# STM32H743 register map
File version: 2.4
CPU: CM7 r0p1, little endian, MPU, FPU, 4 interrupt priority bits
Registers are 32-bit, read-write, reset 0x0 unless marked. A register's access mark holds for its fields unless they carry their own. Offsets are from the block's base; [hi:lo] are bit positions.

## VREFBUF
Base 0x58003C00
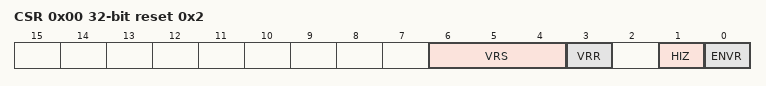
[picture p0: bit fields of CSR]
0x00 CSR access per field reset 0x2 — VREFBUF 控制与状态寄存器
  [6:4] VRS rw — 电压参考量程。这些位用于选择电压参考缓冲器产生的电压值。其他值：保留。
  [3] VRR ro — 电压参考缓冲器就绪
  [1] HIZ rw — 高阻抗模式。此位控制模拟开关与 VREF+ 引脚的连接或断开。有关基于 ENVR 位配置的模式说明，请参见表 196：VREF 缓冲器模式。
  [0] ENVR rw — 电压参考缓冲器模式使能。此位用于使能电压参考缓冲器模式。
0x04 CCR — VREFBUF 校准控制寄存器
  [5:0] TRIM — 微调代码。这些位在复位后会自动加载生产测试期间存入 Flash 的微调值。向这些位写入数据可微调内部参考缓冲器电压。

## IWDG — 独立看门狗
Base 0x58004800
0x00 KR wo — 键寄存器
  [15:0] KEY — 键值（只写，读取返回 0x0000）。软件必须定期向这些位写入键值 0xAAAA，否则当计数器递减到 0 时，看门狗将产生复位。写入键值 0x5555 可使能对 IWDG_PR、IWDG_RLR 和 IWDG_WINR 寄存器的访问（参见第 23.3.6 节：寄存器访问保护）。写入键值 0xCCCC 启动看门狗（选择了硬件看门狗选项时除外）。
0x04 PR — 预分频器寄存器
  [2:0] PR — 预分频器分频系数。这些位受写访问保护，参见第 23.3.6 节：寄存器访问保护。由软件写入，用于选择为计数器提供时钟的预分频器分频系数。要修改预分频器分频系数，必须先将 IWDG_SR 寄存器的 PVU 位复位。注意：读取本寄存器返回的是 VDD 电压域中的预分频器值。若对该寄存器的写操作正在进行中，该值可能不是最新的或无效。因此，仅当 IWDG_SR 寄存器中的 PVU 位复位时，从本寄存器读取的值才有效。
0x08 RLR reset 0xFFF — 重装载寄存器
  [11:0] RL — 看门狗计数器重装载值。这些位受写访问保护，参见第 23.3.6 节。由软件写入，用于定义每次向 IWDG_KR 寄存器写入 0xAAAA 时要装载到看门狗计数器中的值。看门狗计数器从此值开始递减计数。超时周期由该值和时钟预分频器共同决定。有关超时信息，请参阅数据手册。要修改重装载值，必须先将 IWDG_SR 寄存器中的 RVU 位复位。注意：读取本寄存器返回的是 VDD 电压域中的重装载值。若对该寄存器的写操作正在进行中，该值可能不是最新的或无效。因此，仅当 IWDG_SR 寄存器中的 RVU 位复位时，从本寄存器读取的值才有效。
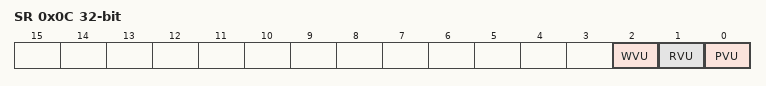
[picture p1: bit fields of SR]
0x0C SR ro — 状态寄存器
  [2] WVU — 看门狗计数器窗口值更新。此位由硬件置 1，表示窗口值更新正在进行中。当重装载值更新操作在 VDD 电压域中完成时（最多需要 5 个 RC 40 kHz 时钟周期），由硬件复位。仅当 WVU 位复位时，才能更新窗口值。仅当 generic window = 1 时才会生成此位。
  [1] RVU — 看门狗计数器重装载值更新。此位由硬件置 1，表示重装载值更新正在进行中。当重装载值更新操作在 VDD 电压域中完成时（最多需要 5 个 RC 40 kHz 时钟周期），由硬件复位。仅当 RVU 位复位时，才能更新重装载值。
  [0] PVU — 看门狗预分频器值更新。此位由硬件置 1，表示预分频器值更新正在进行中。当预分频器更新操作在 VDD 电压域中完成时（最多需要 5 个 RC 40 kHz 时钟周期），由硬件复位。仅当 PVU 位复位时，才能更新预分频器值。
0x10 WINR reset 0xFFF — 窗口寄存器
  [11:0] WIN — 看门狗计数器窗口值。这些位受写访问保护，参见第 23.3.6 节。这些位包含窗口值的高限，用于与递减计数器进行比较。为防止复位，必须在递减计数器的值小于窗口寄存器值且大于 0x0 时对其进行重装载。要修改重装载值，必须先将 IWDG_SR 寄存器中的 WVU 位复位。注意：读取本寄存器返回的是 VDD 电压域中的重装载值。若对该寄存器的写操作正在进行中，该值可能无效。因此，仅当 IWDG_SR 寄存器中的 WVU 位复位时，从本寄存器读取的值才有效。

## WWDG
Base 0x50003000
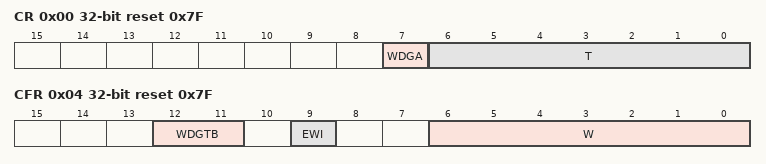
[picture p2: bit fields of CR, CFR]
0x00 CR reset 0x7F — 控制寄存器
  [7] WDGA — 激活位。此位由软件置 1，仅能在复位后由硬件清零。当 WDGA=1 时，看门狗可产生复位。
  [6:0] T — 7 位计数器（MSB 至 LSB）。这些位存储看门狗计数器的值。计数器每 (4096 x 2^WDGTB[1:0]) 个 PCLK 周期递减一次。当计数器从 0x40 递减至 0x3F（T6 被清零）时，将产生复位。
0x04 CFR reset 0x7F — 配置寄存器
  [12:11] WDGTB — 定时器时基。预分频器的时基可如下修改：
  [9] EWI — 提前唤醒中断。此位置 1 后，每当计数器到达 0x40 时即产生中断。此中断仅能在复位后由硬件清零。
  [6:0] W — 7 位窗口值。这些位存储与递减计数器进行比较的窗口值。
0x08 SR — 状态寄存器
  [0] EWIF — 提前唤醒中断标志。当计数器到达 0x40 时，此位由硬件置 1。必须由软件写入 0 来清零，写入 1 无效。即使中断未使能，此位也会被置 1。

## SPI1 — 串行外设接口
Base 0x40013000
Same registers: SPI2 0x40003800, SPI3 0x40003C00, SPI4 0x40013400, SPI5 0x40015000, SPI6 0x58001400
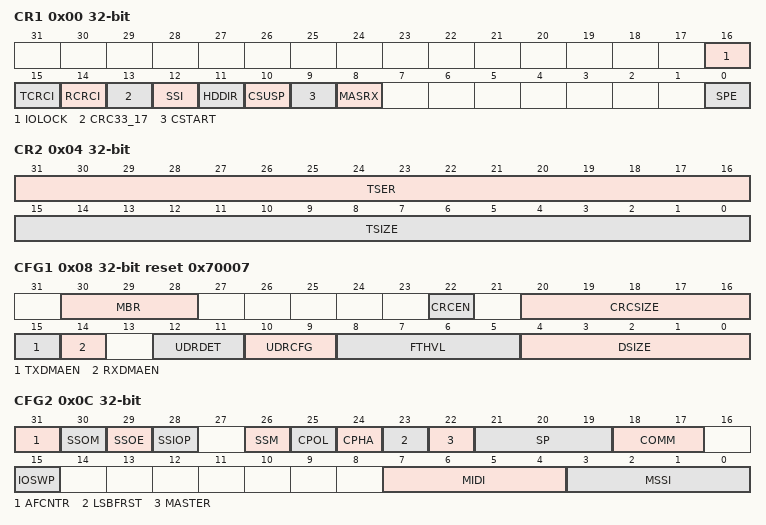
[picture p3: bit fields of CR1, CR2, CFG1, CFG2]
0x00 CR1 access per field — 控制寄存器 1
  [16] IOLOCK ro — 锁定关联 IO 的复用功能配置
  [15] TCRCI rw — 发送器 CRC 计算初始化模式控制
  [14] RCRCI rw — 接收器 CRC 计算初始化模式控制
  [13] CRC33_17 rw — 32 位 CRC 多项式配置
  [12] SSI rw — 内部 SS 信号输入电平
  [11] HDDIR rw — 半双工模式下的收发方向
  [10] CSUSP wo — 主机挂起请求
  [9] CSTART ro — 主机传输启动
  [8] MASRX rw — 接收模式下主机自动挂起
  [0] SPE rw — 串行外设使能
0x04 CR2 access per field — 控制寄存器 2
  [31:16] TSER ro — 上一传输完成后需重新加载到 TSIZE 的扩展数据传输数量
  [15:0] TSIZE rw — 当前传输的数据数量
0x08 CFG1 reset 0x70007 — 配置寄存器 1
  [30:28] MBR — 主机波特率
  [22] CRCEN — 硬件 CRC 计算使能
  [20:16] CRCSIZE — 待传输和比较的 CRC 帧长度
  [15] TXDMAEN — 发送 DMA 流使能
  [14] RXDMAEN — 接收 DMA 流使能
  [12:11] UDRDET — 从机发送器下溢条件检测
  [10:9] UDRCFG — 从机发送器在下溢条件下的行为
  [8:5] FTHVL — 阈值电平
  [4:0] DSIZE — 单个 SPI 数据帧中的位数
0x0C CFG2 — 配置寄存器 2
  [31] AFCNTR — 复用功能 GPIO 控制
  [30] SSOM — 主机模式下 SS 输出管理
  [29] SSOE — SS 输出使能
  [28] SSIOP — SS 输入/输出极性
  [26] SSM — SS 信号输入的软件管理
  [25] CPOL — 时钟极性
  [24] CPHA — 时钟相位
  [23] LSBFRST — 数据帧格式
  [22] MASTER — SPI 主机模式
  [21:19] SP — 串行协议
  [18:17] COMM — SPI 通信模式
  [15] IOSWP — MISO 与 MOSI 引脚交换功能
  [7:4] MIDI — 主机数据间空闲
  [3:0] MSSI — 主机 SS 空闲
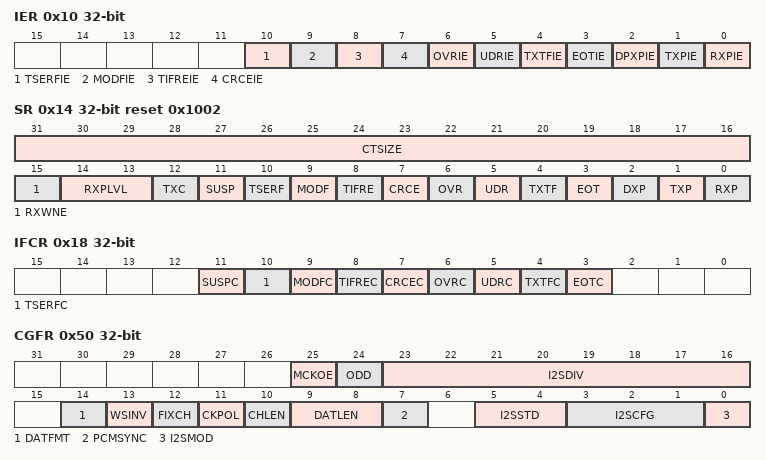
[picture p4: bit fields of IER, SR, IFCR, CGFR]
0x10 IER access per field — 中断使能寄存器
  [10] TSERFIE rw — 额外传输数量重载中断使能
  [9] MODFIE rw — 模式错误中断使能
  [8] TIFREIE rw — TI 帧格式错误中断使能
  [7] CRCEIE rw — CRC 中断使能
  [6] OVRIE rw — 溢出中断使能
  [5] UDRIE rw — 下溢中断使能
  [4] TXTFIE rw — TXTF 中断使能
  [3] EOTIE rw — EOT、SUSP 和 TXC 中断使能
  [2] DPXPIE ro — DXP 中断使能
  [1] TXPIE ro — TXP 中断使能
  [0] RXPIE rw — RXP 中断使能
0x14 SR ro reset 0x1002 — 状态寄存器
  [31:16] CTSIZE — 当前 TSIZE 会话中剩余的数据帧数
  [15] RXWNE — 接收 FIFO 字非空
  [14:13] RXPLVL — 接收 FIFO 打包级别
  [12] TXC — 发送 FIFO 传输完成
  [11] SUSP — 挂起
  [10] TSERF — 额外待传输 SPI 数据量已重载
  [9] MODF — 模式错误
  [8] TIFRE — TI 帧格式错误
  [7] CRCE — CRC 错误
  [6] OVR — 溢出
  [5] UDR — 从机发送模式下的下溢
  [4] TXTF — 传输填充完成
  [3] EOT — 传输结束
  [2] DXP — 双工数据包
  [1] TXP — 发送数据包空间可用
  [0] RXP — 接收数据包可用
0x18 IFCR wo — 中断/状态标志清零寄存器
  [11] SUSPC — 挂起标志清零
  [10] TSERFC — TSERF 标志清零
  [9] MODFC — 模式错误标志清零
  [8] TIFREC — TI 帧格式错误标志清零
  [7] CRCEC — CRC 错误标志清零
  [6] OVRC — 溢出标志清零
  [5] UDRC — 下溢标志清零
  [4] TXTFC — 传输填充完成标志清零
  [3] EOTC — 传输结束标志清零
0x20 TXDR wo — 发送数据寄存器
0x30 RXDR ro — 接收数据寄存器
0x40 CRCPOLY reset 0x107 — 多项式寄存器
  [31:0] CRCPOLY — CRC 多项式寄存器
0x44 TXCRC — 发送器 CRC 寄存器
0x48 RXCRC — 接收器 CRC 寄存器
0x4C UDRDR — 下溢数据寄存器
  [31:0] UDRDR — 从机下溢时的数据
0x50 CGFR — 配置寄存器
  [25] MCKOE — 主时钟输出使能
  [24] ODD — 预分频器奇数因子
  [23:16] I2SDIV — I2S 线性预分频器
  [14] DATFMT — 数据格式
  [13] WSINV — 从机模式下固定通道长度
  [12] FIXCH — 字选择取反
  [11] CKPOL — 串行音频时钟极性
  [10] CHLEN — 通道长度（每个音频通道的位数）
  [9:8] DATLEN — 待传输的数据长度
  [7] PCMSYNC — PCM 帧同步
  [5:4] I2SSTD — I2S 标准选择
  [3:1] I2SCFG — I2S 配置模式
  [0] I2SMOD — I2S 模式选择
